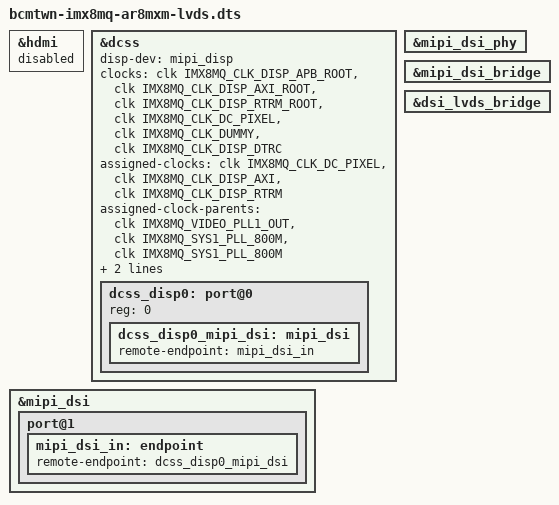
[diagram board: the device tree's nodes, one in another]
/*
 */

#include "bcmtwn-imx8mq-ar8mxm.dts"

&hdmi {
	status = "disabled";
};

&dcss {
	status = "okay";
	disp-dev = "mipi_disp";

	clocks = <&clk IMX8MQ_CLK_DISP_APB_ROOT>,
		 <&clk IMX8MQ_CLK_DISP_AXI_ROOT>,
		 <&clk IMX8MQ_CLK_DISP_RTRM_ROOT>,
		 <&clk IMX8MQ_CLK_DC_PIXEL>,
		 <&clk IMX8MQ_CLK_DUMMY>,
		 <&clk IMX8MQ_CLK_DISP_DTRC>;
	clock-names = "apb", "axi", "rtrm", "pix_div", "pix_out", "dtrc";
	assigned-clocks = <&clk IMX8MQ_CLK_DC_PIXEL>,
			  <&clk IMX8MQ_CLK_DISP_AXI>,
			  <&clk IMX8MQ_CLK_DISP_RTRM>;
	assigned-clock-parents = <&clk IMX8MQ_VIDEO_PLL1_OUT>,
				 <&clk IMX8MQ_SYS1_PLL_800M>,
				 <&clk IMX8MQ_SYS1_PLL_800M>;
	assigned-clock-rates = <594000000>,
			       <800000000>,
			       <400000000>;

	dcss_disp0: port@0 {
		reg = <0>;

		dcss_disp0_mipi_dsi: mipi_dsi {
			remote-endpoint = <&mipi_dsi_in>;
		};
	};
};

&mipi_dsi_phy {
	status = "okay";
};

&mipi_dsi {
	status = "okay";

	port@1 {
		mipi_dsi_in: endpoint {
			remote-endpoint = <&dcss_disp0_mipi_dsi>;
		};
	};
};

&mipi_dsi_bridge {
	status = "okay";
};

&dsi_lvds_bridge {
	status = "okay";
};
